# ISS_CBUFF register map
Vendor: Texas Instruments
Peripheral module from a debugger description file (folder omap4460).
Registers are 32-bit, access per field, reset 0x0 unless marked. A register's access mark holds for its fields unless they carry their own. Offsets are as the file gives them; lines under a group give offsets from that group; [hi:lo] are bit positions; {n}, {i} and the like mark numbered series; 'fields as' and 'values as' point back to an identical list; <NAME> marks a mode.

## ISS_CBUFF
0x00 CBUFF_HL_REVISION ro reset not defined — IP revision identifier (X.Y.R) Used by software to track features, bugs, and compatibility
  [31:0] REVISION — IP Revision
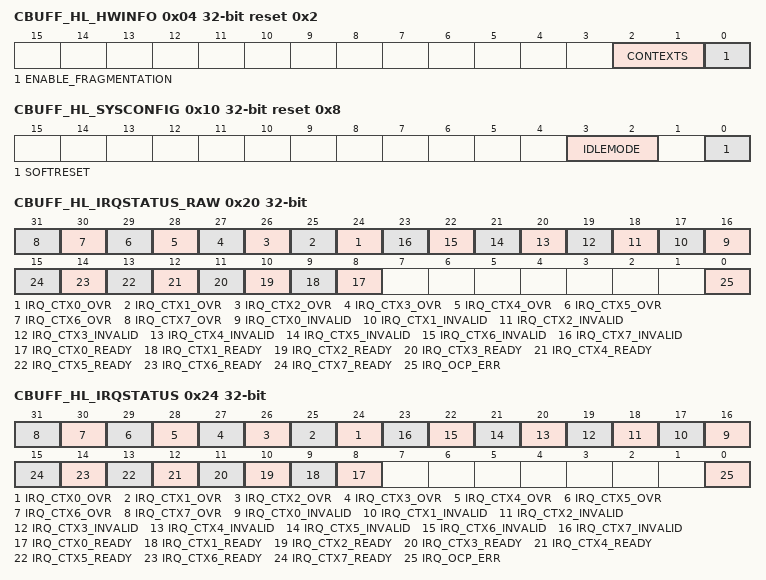
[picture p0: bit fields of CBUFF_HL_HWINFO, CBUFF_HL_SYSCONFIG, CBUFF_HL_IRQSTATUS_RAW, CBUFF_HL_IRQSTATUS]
0x04 CBUFF_HL_HWINFO ro reset 0x2 — Information about the IP module's hardware configuration.
  [2:1] CONTEXTS — Number of contexts
    3=CONTEXTS_3_r (Reserved); 2=CONTEXTS_2_r (8 contexts); 1=CONTEXTS_1_r (4 contexts); 0=CONTEXTS_0_r (2 contexts)
  [0] ENABLE_FRAGMENTATION — Provides information to software if fragmentation support is available
    1=ENABLE_FRAGMENTATION_1_r (Yes); 0=ENABLE_FRAGMENTATION_0_r (No)
0x10 CBUFF_HL_SYSCONFIG reset 0x8 — Clock management configuration
  [3:2] IDLEMODE rw — Configuration of the local target state management mode. By definition, target can handle read/write transaction as long as it is out of IDLE state.
    0=Force-idle mode: local target's idle state follows (acknowledges) the system's idle requests unconditionally, that is, regardless of the IP module's internal requirements. Backup mode, for debug only.; 1=No-idle mode: local target never enters IDLE state. Backup mode, for debug only.; 2=Smart-idle mode: local target's IDLE state eventually follows (acknowledges) the system's IDLE requests, depending on the IP module's internal requirements. IP module shall not generate (IRQ- or DMA-request-related) wake-up events.
  [0] SOFTRESET rw — Software reset
    0=SOFTRESET_0_w (No action); 1=SOFTRESET_1_w (Initiate software reset); 1=SOFTRESET_1_r (Reset (software or other) ongoing); 0=SOFTRESET_0_r (Reset done, no pending action)
0x20 CBUFF_HL_IRQSTATUS_RAW access not given — Per-event raw interrupt status vector. Raw status is set even if event is not enabled. Write 1 to set the (raw) status, mostly for debug.
  [n+24] IRQ_CTX{n}_OVR (n=0..7) — Buffer overflow event. (access RW W1toSet)
    0=IRQ_CTX{n}_OVR_0_w (No action); 1=IRQ_CTX{n}_OVR_1_w (Set event (debug)); 1=IRQ_CTX{n}_OVR_1_r (Event pending); 0=IRQ_CTX{n}_OVR_0_r (No event pending)
  [n+16] IRQ_CTX{n}_INVALID (n=0..7) — Invalid access. (access RW W1toSet)
    0=IRQ_CTX{n}_INVALID_0_w (No action); 1=IRQ_CTX{n}_INVALID_1_w (Set event (debug)); 1=IRQ_CTX{n}_INVALID_1_r (Event pending); 0=IRQ_CTX{n}_INVALID_0_r (No event pending)
  [n+8] IRQ_CTX{n}_READY (n=0..7) — The WB physical window is ready to be accessed by the CPU. (access RW W1toSet)
    0=IRQ_CTX{n}_READY_0_w (No action); 1=IRQ_CTX{n}_READY_1_w (Set event (debug)); 1=IRQ_CTX{n}_READY_1_r (Event pending); 0=IRQ_CTX{n}_READY_0_r (No event pending)
  [0] IRQ_OCP_ERR — OCP error received in the master port. (access RW W1toSet)
    0=IRQ_OCP_ERR_0_w (No action); 1=IRQ_OCP_ERR_1_w (Set event (debug)); 1=IRQ_OCP_ERR_1_r (Event pending); 0=IRQ_OCP_ERR_0_r (No event pending)
0x24 CBUFF_HL_IRQSTATUS access not given — Per-event 'enabled' interrupt status vector. Enabled status is not set unless event is enabled. Write 1 to clear the status after interrupt has been serviced (raw status gets cleared, that is, even if not enabled).
  [n+24] IRQ_CTX{n}_OVR (n=0..7) — Buffer overflow event. (access RW W1toClr)
    0=IRQ_CTX{n}_OVR_0_w (No action); 1=IRQ_CTX{n}_OVR_1_w (Clear (raw) event); 1=IRQ_CTX{n}_OVR_1_r (Event pending); 0=IRQ_CTX{n}_OVR_0_r (No (enabled) event pending)
  [n+16] IRQ_CTX{n}_INVALID (n=0..7) — Invalid access. (access RW W1toClr)
    0=IRQ_CTX{n}_INVALID_0_w (No action); 1=IRQ_CTX{n}_INVALID_1_w (Clear (raw) event); 1=IRQ_CTX{n}_INVALID_1_r (Event pending); 0=IRQ_CTX{n}_INVALID_0_r (No (enabled) event pending)
  [n+8] IRQ_CTX{n}_READY (n=0..7) — The WB physical window is ready to be accessed by the CPU. (access RW W1toClr)
    0=IRQ_CTX{n}_READY_0_w (No action); 1=IRQ_CTX{n}_READY_1_w (Clear (raw) event); 1=IRQ_CTX{n}_READY_1_r (Event pending); 0=IRQ_CTX{n}_READY_0_r (No (enabled) event pending)
  [0] IRQ_OCP_ERR — OCP error received in the master port. (access RW W1toClr)
    0=IRQ_OCP_ERR_0_w (No action); 1=IRQ_OCP_ERR_1_w (Clear (raw) event); 1=IRQ_OCP_ERR_1_r (Event pending); 0=IRQ_OCP_ERR_0_r (No (enabled) event pending)
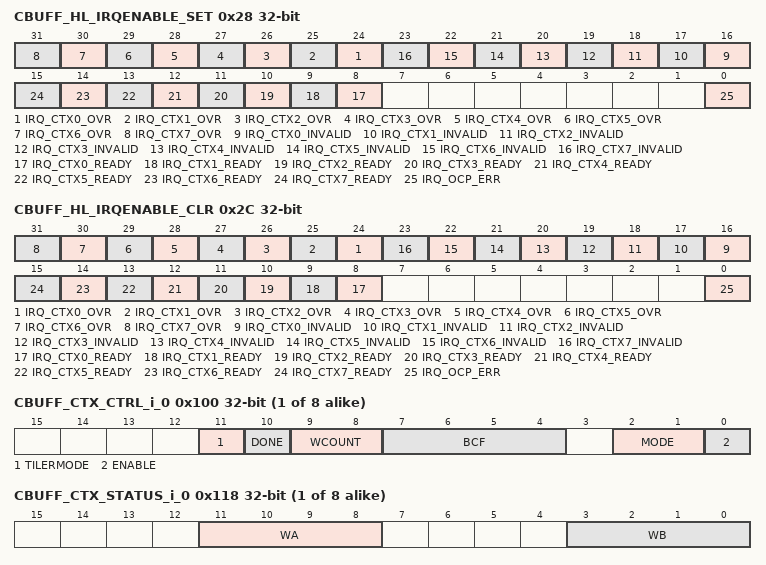
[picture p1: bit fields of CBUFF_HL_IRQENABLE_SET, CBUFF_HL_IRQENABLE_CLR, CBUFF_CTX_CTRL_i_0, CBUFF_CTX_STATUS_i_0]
0x28 CBUFF_HL_IRQENABLE_SET access not given — Per-event interrupt enable bit vector. Write 1 to set (enable interrupt). Readout equal to corresponding _CLR register.
  [n+24] IRQ_CTX{n}_OVR (n=0..7) — Buffer overflow event. (access RW W1toSet)
    0=IRQ_CTX{n}_OVR_0_w (No action); 1=IRQ_CTX{n}_OVR_1_w (Enable interrupt); 1=IRQ_CTX{n}_OVR_1_r (Interrupt enabled); 0=IRQ_CTX{n}_OVR_0_r (Interrupt disabled (masked))
  [n+16] IRQ_CTX{n}_INVALID (n=0..7) — Invalid access. (access RW W1toSet)
    0=IRQ_CTX{n}_INVALID_0_w (No action); 1=IRQ_CTX{n}_INVALID_1_w (Enable interrupt); 1=IRQ_CTX{n}_INVALID_1_r (Interrupt enabled); 0=IRQ_CTX{n}_INVALID_0_r (Interrupt disabled (masked))
  [n+8] IRQ_CTX{n}_READY (n=0..7) — The WB physical window is ready to be accessed by the CPU. (access RW W1toSet)
    0=IRQ_CTX{n}_READY_0_w (No action); 1=IRQ_CTX{n}_READY_1_w (Enable interrupt); 1=IRQ_CTX{n}_READY_1_r (Interrupt enabled); 0=IRQ_CTX{n}_READY_0_r (Interrupt disabled (masked))
  [0] IRQ_OCP_ERR — OCP error received in the master port. (access RW W1toSet)
    0=IRQ_OCP_ERR_0_w (No action); 1=IRQ_OCP_ERR_1_w (Enable interrupt); 1=IRQ_OCP_ERR_1_r (Interrupt enabled); 0=IRQ_OCP_ERR_0_r (Interrupt disabled (masked))
0x2C CBUFF_HL_IRQENABLE_CLR access not given — Per-event interrupt enable bit vector, line 0. Write 1 to clear (disable interrupt). Readout equal to corresponding _SET register.
  [n+24] IRQ_CTX{n}_OVR (n=0..7) — Buffer overflow event. (access RW W1toClr)
    0=IRQ_CTX{n}_OVR_0_w (No action); 1=IRQ_CTX{n}_OVR_1_w (Disable interrupt); 1=IRQ_CTX{n}_OVR_1_r (Interrupt enabled); 0=IRQ_CTX{n}_OVR_0_r (Interrupt disabled (masked))
  [n+16] IRQ_CTX{n}_INVALID (n=0..7) — Invalid access. (access RW W1toClr)
    0=IRQ_CTX{n}_INVALID_0_w (No action); 1=IRQ_CTX{n}_INVALID_1_w (Disable interrupt); 1=IRQ_CTX{n}_INVALID_1_r (Interrupt enabled); 0=IRQ_CTX{n}_INVALID_0_r (Interrupt disabled (masked))
  [n+8] IRQ_CTX{n}_READY (n=0..7) — The WB physical window is ready to be accessed by the CPU. (access RW W1toClr)
    0=IRQ_CTX{n}_READY_0_w (No action); 1=IRQ_CTX{n}_READY_1_w (Disable interrupt); 1=IRQ_CTX{n}_READY_1_r (Interrupt enabled); 0=IRQ_CTX{n}_READY_0_r (Interrupt disabled (masked))
  [0] IRQ_OCP_ERR — OCP error received in the master port. (access RW W1toClr)
    0=IRQ_OCP_ERR_0_w (No action); 1=IRQ_OCP_ERR_1_w (Disable interrupt); 1=IRQ_OCP_ERR_1_r (Interrupt enabled); 0=IRQ_OCP_ERR_0_r (Interrupt disabled (masked))
{0x80+4i} CBUFF_FRAG_ADDR_j_{i} (i=0..15) — Start address of the physical buffer of the CBUFF context 0. This register only exists when fragmentation support is enabled.
  [31:4] ADDR rw — Address, in 128-bit words
{0x100+0x20*i} CBUFF_CTX_CTRL_i_{i} (i=0..7) — Context control register
  [11] TILERMODE rw — Sets the expected value for ADDR[32]. If ADDR[32]=TILERMODE, ADDR[31:4] is processed and eventually translated. Otherwise, the access is handled as transparent, regardless of the other address bits.
  [10] DONE wo — Write this bit to 1 to indicate the CPU has finished processing its physical buffer. This bit is automatically cleared by hardware, reads always return 0. This bit has no effect when MODE=2 (read/write)
    0=DONE_0_w (No effect.); 1=DONE_1_w (The CPU has completely processed the WB physical buffer.)
  [9:8] WCOUNT rw — Window count
    0=2 windows; 1=4 windows; 3=16 windows; 2=8 windows
  [7:4] BCF rw — This register controls the bandwidth control feedback loop output. 0: Control loop disabled. 1-15: The control feedback loop enabled. Behavior depends on functional mode, see , .
  [2:1] MODE rw — Selects the functional mode of this context
    0=Write mode. ISS writes and CPU reads the physical space. CPU accesses are out of the scope of the CBUFF module; therefore, only writes are permitted between CBUFF_CTX_START__x and CBUFF_CTX_END__x.; 1=Read mode. Hardware reads and CPU writes the physical space. CPU accesses are out of the scope of the CBUFF module; therefore, only reads are permitted between CBUFF_CTX_START__x and CBUFF_CTX_END__x.; 2=Read/Write mode. Read and writes are monitored by the CBUFF. WB is used to track current read positions WA is used to track current write position.
  [0] ENABLE rw — Enable/disable
    0=Disables the context. This resets the internal state of the context. All accesses received on OCPI are transmitted to OCPO without modification. Disabling the context takes effect immediately. Software must ensure that no more accesses to the context are outstanding before disabling it. Otherwise memory corruption may occur.; 1=Enable the context. All accesses between CBUFF_CTX_START__x and CBUFF_CTX_END__x are processed by the CBUFF.
{0x104+0x20*i} CBUFF_CTX_START_i_{i} (i=0..7) — Start address of the virtual space managed by the context
  [31:4] ADDR rw — Address, in 128-bit words
{0x108+0x20*i} CBUFF_CTX_END_i_{i} (i=0..7) — End address of the virtual space managed by the context
  [31:4] ADDR rw — Address, in 128-bit words
{0x10C+0x20*i} CBUFF_CTX_WINDOWSIZE_i_{i} (i=0..7) — Defines the size of a window
  [23:4] SIZE rw — Size, in 128-bit words
{0x110+0x20*i} CBUFF_CTX_THRESHOLD_F_i_{i} (i=0..7) — Threshold value used to check if a write window is full
  [23:0] THRESHOLD rw — Threshold value, in bytes
{0x114+0x20*i} CBUFF_CTX_THRESHOLD_S_i_{i} (i=0..7) — Threshold value used to control the BCF synchronization mechanism
  [23:0] THRESHOLD rw — Threshold value, in bytes
{0x118+0x20*i} CBUFF_CTX_STATUS_i_{i} ro (i=0..7) — Status register
  [11:8] WA — Valid values depend on the CBUFF_CTX_CTRL__x.WCOUNT register.
  [3:0] WB — Valid values depend on the CBUFF_CTX_CTRL__x.WCOUNT register.
{0x11C+0x20*i} CBUFF_CTX_PHY_i_{i} (i=0..7) — Start address of the first physical buffer managed by the context when fragmentation support is disabled.
  [31:4] ADDR rw — Address, in 128 bit words.
